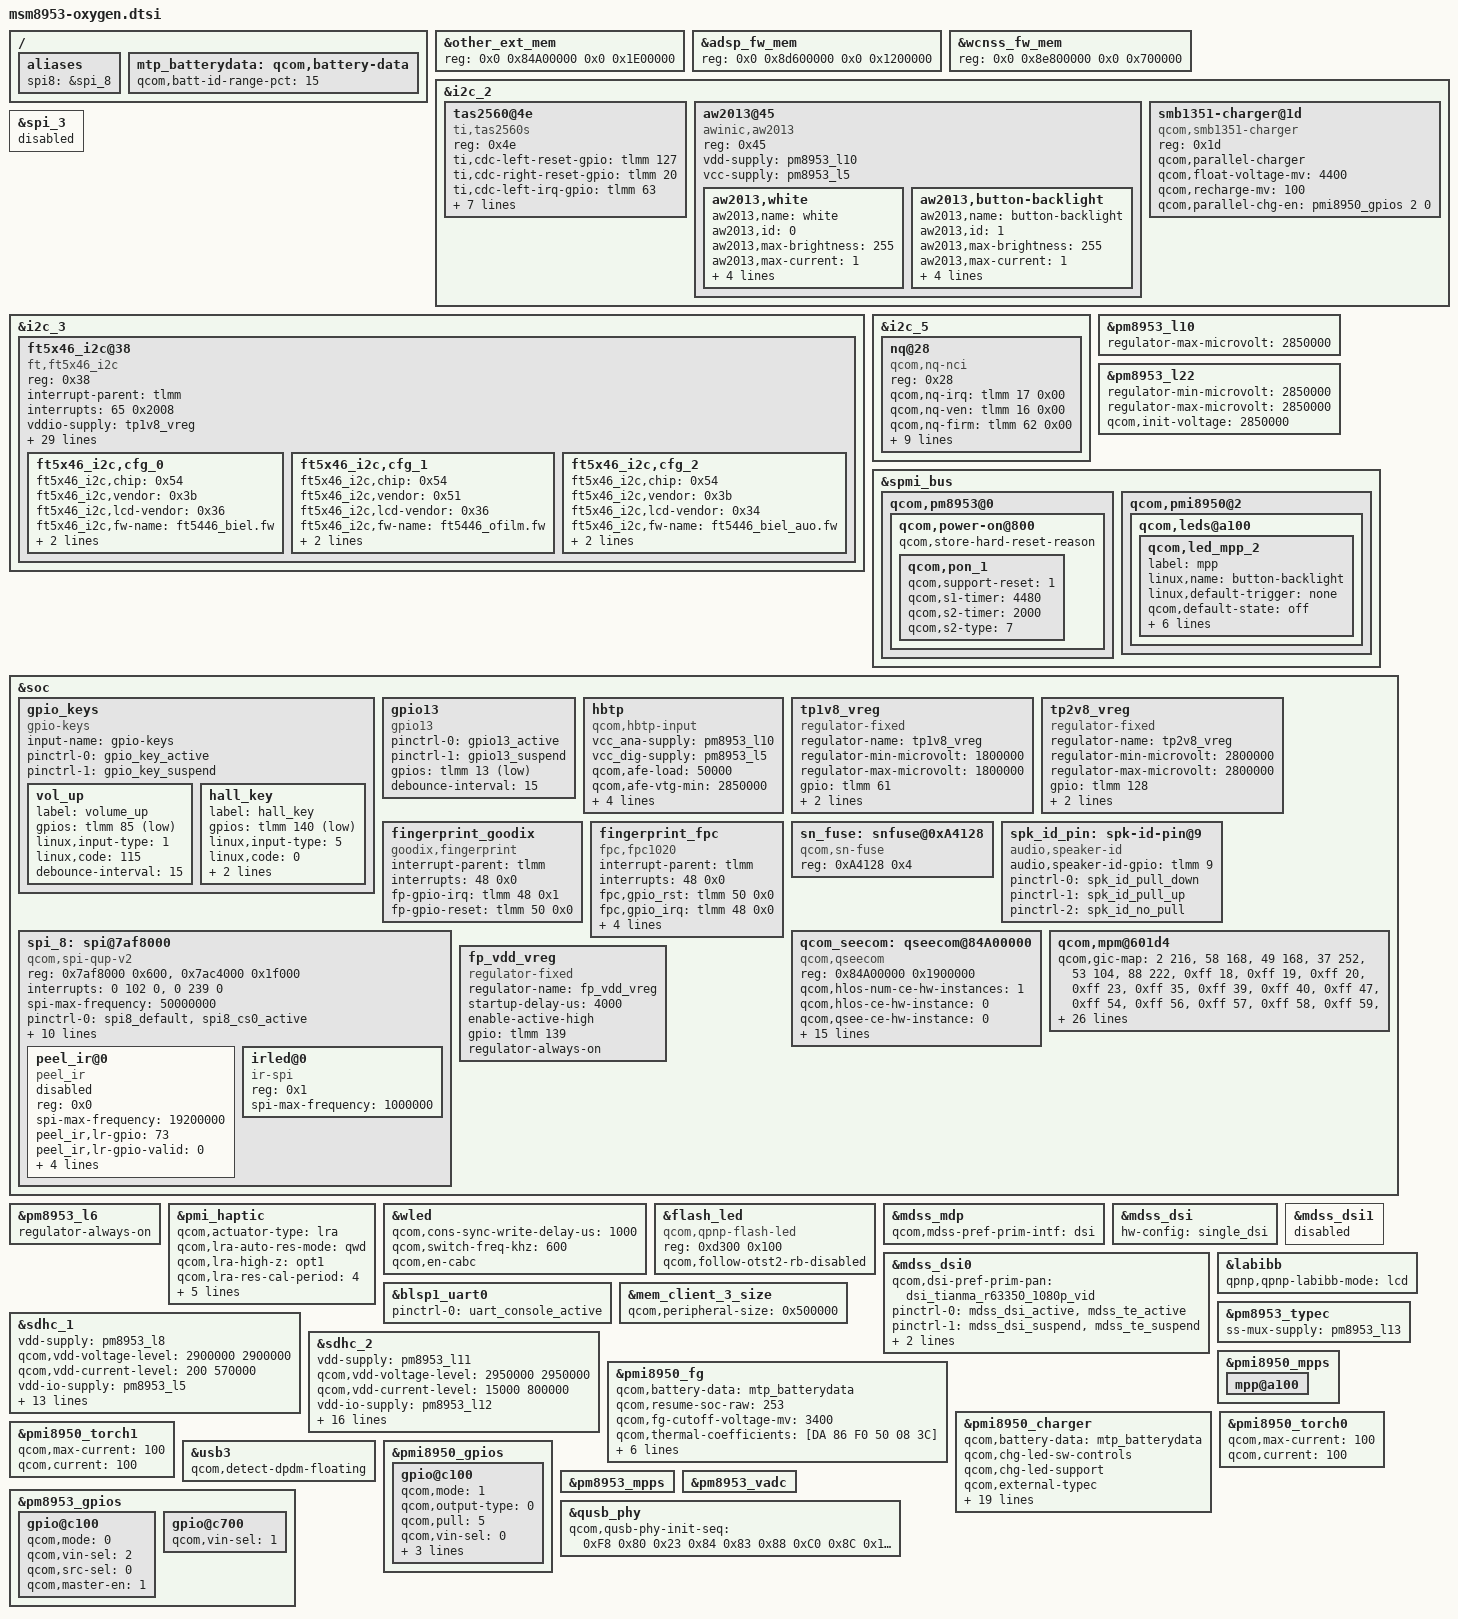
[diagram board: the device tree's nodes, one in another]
/*
 * Copyright (c) 2015-2016, The Linux Foundation. All rights reserved.
 * Copyright (C) 2017 XiaoMi, Inc.
 *
 * This program is free software; you can redistribute it and/or modify
 * it under the terms of the GNU General Public License version 2 and
 * only version 2 as published by the Free Software Foundation.
 *
 * This program is distributed in the hope that it will be useful,
 * but WITHOUT ANY WARRANTY; without even the implied warranty of
 * MERCHANTABILITY or FITNESS FOR A PARTICULAR PURPOSE.  See the
 * GNU General Public License for more details.
 */

#include "msm8953-oxygen-audio.dtsi"
#include "msm8953-oxygen-camera-sensor-mtp.dtsi"
//#include "msm8953-oxygen-mdss-panels.dtsi"
#include "msm8953-oxygen-pinctrl.dtsi"

#include "dsi-panel-tianma-r63350-1080p-video.dtsi"
#include "dsi-panel-auo-r61322-1080p-video.dtsi"

/ {
	aliases {
		spi8 = &spi_8;
	};
};

&other_ext_mem {
    reg = <0x0 0x84A00000 0x0 0x1E00000>;
};

&adsp_fw_mem {
    reg = <0x0 0x8d600000 0x0 0x1200000>;
};

&wcnss_fw_mem {
    reg = <0x0 0x8e800000 0x0 0x700000>;
};

&i2c_2 {
    /delete-node/ adv7533@39;
};

&spi_3 {
	status = "disabled";
};

&i2c_3 { /* BLSP1 QUP3 (TP) */
	status = "okay";
	ft5x46_i2c@38 {
		compatible = "ft,ft5x46_i2c";
		reg = <0x38>;
		interrupt-parent = <&tlmm>;
		interrupts = <65 0x2008>;
		vddio-supply = <&tp1v8_vreg>;
		vdd-supply = <&tp2v8_vreg>;
		/* pins used by touchscreen */
		pinctrl-names = "pmx_ts_active","pmx_ts_suspend";
		pinctrl-0 = <&ts_int_active &ts_reset_active>;
		pinctrl-1 = <&ts_int_suspend &ts_reset_suspend>;
		ft5x46_i2c,i2c-pull-up;
		ft5x46_i2c,irqflags = <0x2008>;
		ft5x46_i2c,x-max = <1080>;
		ft5x46_i2c,y-max = <1920>;
		ft5x46_i2c,z-max = <255>;
		ft5x46_i2c,w-max = <200>;
		ft5x46_i2c,reset-gpio = <&tlmm 64 0x00>;
		ft5x46_i2c,irq-gpio = <&tlmm 65 0x2008>;
		ft5x46_i2c,landing-jiffies = <1000>;
		ft5x46_i2c,landing-threshold = <16>;
		ft5x46_i2c,staying-threshold = <8>;
		ft5x46_i2c,raw-min = <7000>;
		ft5x46_i2c,raw-max = <10000>;
		ft5x46_i2c,has-key;
		ft5x46_i2c,key-rx1 = <4>;
		ft5x46_i2c,key-rx2 = <8>;
		ft5x46_i2c,key-rx3 = <12>;
		ft5x46_i2c,open-min = <4000>;
		ft5x46_i2c,imin-cc = <500>;
		ft5x46_i2c,imin-cg = <500>;
		ft5x46_i2c,fw-delay-55-ms = <2>;
		ft5x46_i2c,fw-delay-aa-ms = <2>;
		ft5x46_i2c,fw-upgrade-id1 = <0x54>;
		ft5x46_i2c,fw-upgrade-id2 = <0x2C>;
		ft5x46_i2c,fw-delay-readid-ms = <20>;
		ft5x46_i2c,firmware-array-size = <3>;
		ft5x46_i2c,cfg_0 {
			ft5x46_i2c,chip = <0x54>;
			ft5x46_i2c,vendor = <0x3b>;
			ft5x46_i2c,lcd-vendor = <0x36>;
			ft5x46_i2c,fw-name = "ft5446_biel.fw";
			ft5x46_i2c,tx-num = <24>;
			ft5x46_i2c,rx-num = <13>;
		};
		ft5x46_i2c,cfg_1 {
			ft5x46_i2c,chip = <0x54>;
			ft5x46_i2c,vendor = <0x51>;
			ft5x46_i2c,lcd-vendor = <0x36>;
			ft5x46_i2c,fw-name = "ft5446_ofilm.fw";
			ft5x46_i2c,tx-num = <24>;
			ft5x46_i2c,rx-num = <13>;
		};
		ft5x46_i2c,cfg_2 {
			ft5x46_i2c,chip = <0x54>;
			ft5x46_i2c,vendor = <0x3b>;
			ft5x46_i2c,lcd-vendor = <0x34>;
			ft5x46_i2c,fw-name = "ft5446_biel_auo.fw";
			ft5x46_i2c,tx-num = <24>;
			ft5x46_i2c,rx-num = <13>;
		};
	};
};

&i2c_2 { /* BLSP2 QUP1 (TAS2560) */
	tas2560@4e {
		compatible = "ti,tas2560s";
		reg = <0x4e>;
		ti,cdc-left-reset-gpio = <&tlmm 127 0>;
		ti,cdc-right-reset-gpio = <&tlmm 20 0>;
		ti,cdc-left-irq-gpio = <&tlmm 63 0>;
		ti,cdc-right-irq-gpio = <&tlmm 21 0>;
		ti,left-channel = <0x4f>;
		ti,right-channel = <0x4c>;
		ti,left-load = <0>;   /* 0, 8Ohm; 1, 6Ohm; 2, 4Ohm */
		ti,right-load-aac = <0>;   /* 0, 8Ohm; 1, 6Ohm; 2, 4Ohm */
		ti,right-load-ssi = <0>;   /* 0, 8Ohm; 1, 6Ohm; 2, 4Ohm */
		ti,spk-id-pin = <&spk_id_pin>;

	};

	aw2013@45 {
		compatible = "awinic,aw2013";
		reg = <0x45>;
		vdd-supply = <&pm8953_l10>;
		vcc-supply = <&pm8953_l5>;

		aw2013,white {
			aw2013,name = "white";
			aw2013,id = <0>;
			aw2013,max-brightness = <255>;
			aw2013,max-current = <1>;
			aw2013,rise-time-ms = <3>;
			aw2013,hold-time-ms = <2>;
			aw2013,fall-time-ms = <3>;
			aw2013,off-time-ms = <2>;
		};
		aw2013,button-backlight {
			aw2013,name = "button-backlight";
			aw2013,id = <1>;
			aw2013,max-brightness = <255>;
			aw2013,max-current = <1>;
			aw2013,rise-time-ms = <3>;
			aw2013,hold-time-ms = <2>;
			aw2013,fall-time-ms = <3>;
			aw2013,off-time-ms = <2>;
		};
	};
};

&i2c_5 { /* BLSP2 QUP1 (NFC) */
	nq@28 {
		compatible = "qcom,nq-nci";
		reg = <0x28>;
		qcom,nq-irq = <&tlmm 17 0x00>;
		qcom,nq-ven = <&tlmm 16 0x00>;
		qcom,nq-firm = <&tlmm 62 0x00>;
		qcom,nq-clkreq = <&pm8953_gpios 2 0x00>;
		qcom,nq-esepwr = <&tlmm 141 0x00>;
		interrupt-parent = <&tlmm>;
		qcom,clk-src = "BBCLK2";
		interrupts = <17 0>;
		interrupt-names = "nfc_irq";
		pinctrl-names = "nfc_active", "nfc_suspend";
		pinctrl-0 = <&nfc_int_active &nfc_disable_active>;
		pinctrl-1 = <&nfc_int_suspend &nfc_disable_suspend>;
		clocks = <&clock_gcc clk_bb_clk2_pin>;
		clock-names = "ref_clk";
	};

};

&pm8953_l10 {
	regulator-max-microvolt = <2850000>;
};

&pm8953_l22 {
    regulator-min-microvolt = <2850000>;
    regulator-max-microvolt = <2850000>;
    qcom,init-voltage = <2850000>;
};

&spmi_bus {
    qcom,pm8953@0 {
        qcom,power-on@800 {
            qcom,store-hard-reset-reason;
            qcom,pon_1 {
				qcom,support-reset = <1>;
				qcom,s1-timer = <4480>;
				qcom,s2-timer = <2000>;
				qcom,s2-type = <7>;
			};
		};
    };

	qcom,pmi8950@2 {
        qcom,leds@a100 {
			qcom,led_mpp_2 {
				label = "mpp";
				linux,name = "button-backlight";
				linux,default-trigger = "none";
				qcom,default-state = "off";
				qcom,max-current = <40>;
				qcom,current-setting = <5>;
				qcom,id = <6>;
				qcom,source-sel = <1>;
				qcom,mode-ctrl = <0x60>;
				qcom,mode = "manual";
			};
        };
	};
};

&soc {
	gpio_keys {
		compatible = "gpio-keys";
		input-name = "gpio-keys";
		pinctrl-names = "tlmm_gpio_key_active","tlmm_gpio_key_suspend";
		pinctrl-0 = <&gpio_key_active>;
		pinctrl-1 = <&gpio_key_suspend>;

		vol_up {
			label = "volume_up";
			gpios = <&tlmm 85 0x1>;
			linux,input-type = <1>;
			linux,code = <115>;
			debounce-interval = <15>;
		};
		hall_key {
			label = "hall_key";
			gpios = <&tlmm 140 0x01>;
			linux,input-type = <5>;
			linux,code = <0>;
			gpio-key,wakeup;
			debounce-interval = <15>;
		};

	};

	gpio13 {
		pinctrl-names = "tlmm_gpio13_active","tlmm_gpio13_suspend";
		pinctrl-0 = <&gpio13_active>;
		pinctrl-1 = <&gpio13_suspend>;
		compatible = "gpio13";
		gpios = <&tlmm 13 0x01>;
		debounce-interval = <15>;
	};

	hbtp {
		compatible = "qcom,hbtp-input";
		vcc_ana-supply = <&pm8953_l10>;
		vcc_dig-supply = <&pm8953_l5>;
		qcom,afe-load = <50000>;
		qcom,afe-vtg-min = <2850000>;
		qcom,afe-vtg-max = <2850000>;
		qcom,dig-load = <15000>;
		qcom,dig-vtg-min = <1800000>;
		qcom,dig-vtg-max = <1800000>;
	};

	tp1v8_vreg: tp1v8_vreg {
		compatible = "regulator-fixed";
		regulator-name = "tp1v8_vreg";
		regulator-min-microvolt = <1800000>;
		regulator-max-microvolt = <1800000>;
		gpio = <&tlmm 61 0>;
		startup-delay-us = <5000>;
		enable-active-high;
	};

	tp2v8_vreg: tp2v8_vreg {
		compatible = "regulator-fixed";
		regulator-name = "tp2v8_vreg";
		regulator-min-microvolt = <2800000>;
		regulator-max-microvolt = <2800000>;
		gpio = <&tlmm  128 0>;
		startup-delay-us = <5000>;
		enable-active-high;
	};

	fingerprint_goodix {
		compatible = "goodix,fingerprint";
		interrupt-parent = <&tlmm>;
		interrupts = <48 0x0>;
		fp-gpio-irq = <&tlmm 48 0x1>;
		fp-gpio-reset = <&tlmm 50 0x0>;
		status = "okay";
	};
	fingerprint_fpc {
		status = "okay";
		compatible = "fpc,fpc1020";
		interrupt-parent = <&tlmm>;
		interrupts = <48 0x0>;
		fpc,gpio_rst = <&tlmm 50 0x0>;
		fpc,gpio_irq = <&tlmm 48 0x0>;
		vdd_ana-supply  = <&fp_vdd_vreg>;
		/* fpc,enable-on-boot; */
		/* fpc,enable-wakeup; */

		pinctrl-names = "fpc1020_reset_reset",
				"fpc1020_reset_active",
				"fpc1020_irq_active";

		pinctrl-0 = <&msm_gpio_50>;
		pinctrl-1 = <&msm_gpio_50_output_high>;
		pinctrl-2 = <&msm_gpio_48>;
	};

	sn_fuse: snfuse@0xA4128 {
		compatible = "qcom,sn-fuse";
		reg = <0xA4128 0x4>;
		reg-names = "sn-base";
	};

	spk_id_pin: spk-id-pin@9 {
		compatible = "audio,speaker-id";
		audio,speaker-id-gpio = <&tlmm 9 0x00>;
		pinctrl-names = "pull_down", "pull_up", "no_pull";
		pinctrl-0 = <&spk_id_pull_down>;
		pinctrl-1 = <&spk_id_pull_up>;
		pinctrl-2 = <&spk_id_no_pull>;
	};

	spi_8: spi@7af8000 { /* BLSP2 QUP4 */
		status = "ok";
		compatible = "qcom,spi-qup-v2";
		#address-cells = <1>;
		#size-cells = <0>;
		reg-names = "spi_physical", "spi_bam_physical";
		reg = <0x7af8000 0x600>,
			<0x7ac4000 0x1f000>;
		interrupt-names = "spi_irq", "spi_bam_irq";
		interrupts = <0 102 0>, <0 239 0>;
		spi-max-frequency = <50000000>;
		pinctrl-names = "spi_default", "spi_sleep";
		pinctrl-0 = <&spi8_default &spi8_cs0_active>;
		pinctrl-1 = <&spi8_sleep &spi8_cs0_sleep>;
		clocks = <&clock_gcc clk_gcc_blsp2_ahb_clk>,
			<&clock_gcc clk_gcc_blsp2_qup4_spi_apps_clk>;
		clock-names = "iface_clk", "core_clk";
		qcom,infinite-mode = <0>;
		qcom,use-bam;
		qcom,use-pinctrl;
		qcom,ver-reg-exists;
		qcom,bam-consumer-pipe-index = <10>;
		qcom,bam-producer-pipe-index = <11>;
		qcom,master-id = <84>;

		peel_ir@0 {
			compatible = "peel_ir";
			reg = <0x0>;
			spi-max-frequency = <19200000>;
			peel_ir,lr-gpio = <73>;
			peel_ir,lr-gpio-valid = <0>;
			peel_ir,spi-bpw = <32>;
			peel_ir,spi-clk-speed = <960000>;
			peel_ir,spi-mode = <0>;
			peel_ir,peel-field = <2345>;
			status = "disabled";
		};
		irled@0 {
			compatible = "ir-spi";
			reg = <0x1>;
			status = "ok";
			spi-max-frequency = <1000000>;
		};
	};

	/delete-node/ qseecom@85b00000;

	qcom_seecom: qseecom@84A00000 {
		compatible = "qcom,qseecom";
		reg = <0x84A00000 0x1900000>;
		reg-names = "secapp-region";
		qcom,hlos-num-ce-hw-instances = <1>;
		qcom,hlos-ce-hw-instance = <0>;
		qcom,qsee-ce-hw-instance = <0>;
		qcom,disk-encrypt-pipe-pair = <2>;
		qcom,support-fde;
		qcom,msm-bus,name = "qseecom-noc";
		qcom,msm-bus,num-cases = <4>;
		qcom,msm-bus,num-paths = <1>;
		qcom,support-bus-scaling;
		qcom,appsbl-qseecom-support;
		qcom,msm-bus,vectors-KBps =
			<55 512 0 0>,
			<55 512 0 0>,
			<55 512 120000 1200000>,
			<55 512 393600 3936000>;
		clocks = <&clock_gcc clk_crypto_clk_src>,
			 <&clock_gcc clk_gcc_crypto_clk>,
			 <&clock_gcc clk_gcc_crypto_ahb_clk>,
			 <&clock_gcc clk_gcc_crypto_axi_clk>;
		clock-names = "core_clk_src", "core_clk",
				"iface_clk", "bus_clk";
		qcom,ce-opp-freq = <100000000>;
	};

    qcom,mpm@601d4 {
        qcom,gic-map = <2 216>, /* tsens_upper_lower_int */
			<58 168>,   /* qusb2phy_dmse_hv -> hs_phy_irq*/
			<49 168>,   /* qusb2phy_dpse_hv -> hs_phy_irq*/
			<37 252>,   /* qmp_usb3_lfps_rxterm_irq -> ss_phy_irq */
			<53 104>, /* mdss_irq */
			<88 222>, /* ee0_krait_hlos_spmi_periph_irq */
			<0xff 18>,  /* APC_qgicQTmrSecPhysIrptReq */
			<0xff 19>,  /* APC_qgicQTmrNonSecPhysIrptReq */
			<0xff 20>,  /* qgicQTmrVirtIrptReq */
			<0xff 23>,  /* apss_hm */
			<0xff 35>,  /* WDT_barkInt */
			<0xff 39>,  /* arch_mem_timer */
			<0xff 40>,  /* qtmr_phy_irq[0] */
			<0xff 47>,  /* rbif_irq[0] */
			<0xff 54>,  /* gladiator-error */
			<0xff 56>,  /* q6_wdog_expired_irq */
			<0xff 57>,  /* mss_to_apps_irq(0) */
			<0xff 58>,  /* mss_to_apps_irq(1) */
			<0xff 59>,  /* mss_to_apps_irq(2) */
			<0xff 60>,  /* mss_to_apps_irq(3) */
			<0xff 61>,  /* mss_a2_bam_irq */
			<0xff 65>,  /* o_gc_sys_irq[0] */
			<0xff 69>,  /* vbif_irpt */
			<0xff 73>,  /* app_tcu_gbl_flt_irpt_ns */
			<0xff 74>,  /* smmu_bus_intr[2] */
			<0xff 75>,  /* smmu_bus_intr[3] */
			<0xff 78>,  /* smmu_bus_intr[5] */
			<0xff 79>,  /* smmu_bus_intr[6] */
			<0xff 85>,  /* smmu_bus_intr[31] */
			<0xff 86>,  /* smmu_bus_intr[32] */
			<0xff 90>,  /* smmu_bus_intr[33] */
			<0xff 92>,  /* smmu_bus_intr[34] */
			<0xff 93>,  /* smmu_bus_intr[35] */
			<0xff 97>,  /* smmu_bus_intr[10] */
			<0xff 102>, /* smmu_bus_intr[14] */
			<0xff 108>, /* smmu_bus_intr[36] */
			<0xff 109>, /* smmu_bus_intr[37] */
			<0xff 112>, /* smmu_bus_intr[38] */
			<0xff 114>, /* qdsd_intr_out */
			<0xff 126>, /* app_tcu_cxt_irpt_vec[11] */
			<0xff 128>, /* blsp1_peripheral_irq[3] */
			<0xff 131>, /* qup_irq */
			<0xff 136>, /* app_tcu_cxt_irpt_vec[15] */
			<0xff 137>, /* app_tcu_cxt_irpt_vec[16] */
			<0xff 138>, /* app_tcu_cxt_irpt_vec[17] */
			<0xff 139>, /* uart_dm_intr */
			<0xff 140>, /* uart_dm_intr */
			<0xff 141>, /* app_tcu_cxt_irpt_vec[18] */
			<0xff 142>, /* smmu_bus_intr[47] */
			<0xff 143>, /* smmu_bus_intr[48] */
			<0xff 144>, /* smmu_bus_intr[49] */
			<0xff 145>, /* smmu_bus_intr[50] */
			<0xff 146>, /* smmu_bus_intr[51] */
			<0xff 147>, /* smmu_bus_intr[52] */
			<0xff 148>, /* smmu_bus_intr[53] */
			<0xff 149>, /* smmu_bus_intr[54] */
			<0xff 150>, /* smmu_bus_intr[55] */
			<0xff 151>, /* smmu_bus_intr[56] */
			<0xff 152>, /* smmu_bus_intr[57] */
			<0xff 153>, /* smmu_bus_intr[58] */
			<0xff 155>, /* sdc1_irq(0) */
			<0xff 157>, /* sdc2_irq(0) */
			<0xff 166>, /* usb30_pwr_evnt_irq */
			<0xff 167>, /* usb30_bam_irq[0] */
			<0xff 170>, /* sdc1_pwr_cmd_irq */
			<0xff 172>, /* usb30_ctrl_irq[0] */
			<0xff 173>, /* o_wcss_apss_smd_hi */
			<0xff 174>, /* o_wcss_apss_smd_med */
			<0xff 175>, /* o_wcss_apss_smd_low */
			<0xff 176>, /* o_wcss_apss_smsm_irq */
			<0xff 177>, /* o_wcss_apss_wlan_data_xfer_done */
			<0xff 178>, /* o_wcss_apss_wlan_rx_data_avail */
			<0xff 179>, /* o_wcss_apss_asic_intr */
			<0xff 181>, /* o_wcss_apss_wdog_bite_and_reset_rdy */
			<0xff 188>, /* lpass_irq_out_apcs(0) */
			<0xff 189>, /* lpass_irq_out_apcs(1) */
			<0xff 190>, /* lpass_irq_out_apcs(2) */
			<0xff 191>, /* lpass_irq_out_apcs(3) */
			<0xff 192>, /* lpass_irq_out_apcs(4) */
			<0xff 193>, /* lpass_irq_out_apcs(5) */
			<0xff 194>, /* lpass_irq_out_apcs(6) */
			<0xff 195>, /* lpass_irq_out_apcs(7) */
			<0xff 196>, /* lpass_irq_out_apcs(8) */
			<0xff 197>, /* lpass_irq_out_apcs(9) */
			<0xff 198>, /* coresight-tmc-etr interrupt */
			<0xff 200>, /* rpm_ipc(4) */
			<0xff 201>, /* rpm_ipc(5) */
			<0xff 202>, /* rpm_ipc(6) */
			<0xff 203>, /* rpm_ipc(7) */
			<0xff 204>, /* rpm_ipc(24) */
			<0xff 205>, /* rpm_ipc(25) */
			<0xff 206>, /* rpm_ipc(26) */
			<0xff 207>, /* rpm_ipc(27) */
			<0xff 212>, /* lpass_slimbus_bam_ee1_irq */
			<0xff 215>, /* o_bimc_intr[0] */
			<0xff 224>, /* spdm_realtime_irq[1] */
			<0xff 231>, /* arm-smmu global fault */
			<0xff 239>, /* crypto_bam_irq[1]*/
			<0xff 240>, /* summary_irq_kpss */
			<0xff 253>, /* sdc2_pwr_cmd_irq */
			<0xff 257>, /* osmmu_Cirpt[0] */
			<0xff 260>, /* ipa_irq[0] */
			<0xff 262>, /* ipa_bam_irq[0] */
			<0xff 263>, /* ipa_bam_irq[2] */
			<0xff 264>, /* arm-smmu context fault */
			<0xff 269>, /* rpm_wdog_expired_irq */
			<0xff 270>, /* blsp1_bam_irq[0] */
			<0xff 271>, /* Added by Xiaomi */
			<0xff 273>, /* smmu_bus_intr[18] */
			<0xff 274>, /* smmu_bus_intr[19] */
			<0xff 275>, /* rpm_ipc(30) */
			<0xff 276>, /* rpm_ipc(31) */
			<0xff 285>, /* app_tcu_cxt_irpt_vec[0] */
			<0xff 286>, /* app_tcu_cxt_irpt_vec[1] */
			<0xff 287>, /* app_tcu_cxt_irpt_vec[2] */
			<0xff 305>, /* L2_EXTERRIRQ_C0 */
			<0xff 306>, /* L2_EXTERRIRQ_C1 */
			<0xff 307>, /* L2_INTERRIRQ_C0 */
			<0xff 308>, /* L2_INTERRIRQ_C1 */
			<0xff 314>, /* CCISAW_svicInt */
			<0xff 321>, /* q6ss_irq_out(4) */
			<0xff 322>, /* q6ss_irq_out(5) */
			<0xff 323>, /* q6ss_irq_out(6) */
			<0xff 325>, /* q6ss_wdog_exp_irq */
			<0xff 344>, /* sdcc_ice_nonsec_level_irq */
			<0xff 346>; /* tsens_critical_int */
    };

    /delete-node/ eldo2;

    fp_vdd_vreg: fp_vdd_vreg {
		compatible = "regulator-fixed";
		regulator-name = "fp_vdd_vreg";
		startup-delay-us = <4000>;
		enable-active-high;
		gpio = <&tlmm 139 0>;
	};
};


&fp_vdd_vreg {
	regulator-always-on;
};

&pm8953_l6 {
	regulator-always-on;
};

&pmi_haptic{
	qcom,actuator-type = "lra";
	qcom,lra-auto-res-mode="qwd";
	qcom,lra-high-z="opt1";
	qcom,lra-res-cal-period = <4>;
	qcom,wave-play-rate-us = <5100>;
	qcom,wave-shape = "sine";
	qcom,vmax-mv = <2088>;
	qcom,brake-pattern = [03 02 01 00];
	qcom,misc-trim-error-rc19p2-clk-reg-present;
};

&wled {
	qcom,cons-sync-write-delay-us = <1000>;
    qcom,switch-freq-khz = <600>;
    /delete-property/ qcom,en-ext-pfet-sc-pro;
    qcom,en-cabc;
};

&flash_led {
	compatible = "qcom,qpnp-flash-led";
	reg = <0xd300 0x100>;
	qcom,follow-otst2-rb-disabled;
};

&mdss_mdp {
	qcom,mdss-pref-prim-intf = "dsi";
};

&mdss_dsi {
	hw-config = "single_dsi";
};

&mdss_dsi0 {
	qcom,dsi-pref-prim-pan = <&dsi_tianma_r63350_1080p_vid>;
	pinctrl-names = "mdss_default", "mdss_sleep";
	pinctrl-0 = <&mdss_dsi_active &mdss_te_active>;
	pinctrl-1 = <&mdss_dsi_suspend &mdss_te_suspend>;

	qcom,platform-te-gpio = <&tlmm 24 0>;
	qcom,platform-reset-gpio = <&tlmm 35 0>;

	/delete-property/ vdd-supply;
};

&mdss_dsi1 {
	status = "disabled";
};

&labibb {
	status = "ok";
	qpnp,qpnp-labibb-mode = "lcd";
};

&blsp1_uart0 {
	status = "ok";
	pinctrl-names = "default";
	pinctrl-0 = <&uart_console_active>;
};

&mem_client_3_size {
	qcom,peripheral-size = <0x500000>;
};

&sdhc_1 {
	/* device core power supply */
	vdd-supply = <&pm8953_l8>;
	qcom,vdd-voltage-level = <2900000 2900000>;
	qcom,vdd-current-level = <200 570000>;

	/* device communication power supply */
	vdd-io-supply = <&pm8953_l5>;
	qcom,vdd-io-always-on;
	qcom,vdd-io-lpm-sup;
	qcom,vdd-io-voltage-level = <1800000 1800000>;
	qcom,vdd-io-current-level = <200 325000>;

	pinctrl-names = "active", "sleep";
	pinctrl-0 = <&sdc1_clk_on &sdc1_cmd_on &sdc1_data_on  &sdc1_rclk_on>;
	pinctrl-1 = <&sdc1_clk_off &sdc1_cmd_off &sdc1_data_off &sdc1_rclk_off>;

	qcom,clk-rates = <400000 20000000 25000000 50000000 100000000 192000000
								384000000>;
	qcom,nonremovable;
	qcom,bus-speed-mode = "HS400_1p8v", "HS200_1p8v", "DDR_1p8v";

	status = "ok";
};

&sdhc_2 {
	/* device core power supply */
	vdd-supply = <&pm8953_l11>;
	qcom,vdd-voltage-level = <2950000 2950000>;
	qcom,vdd-current-level = <15000 800000>;

	/* device communication power supply */
	vdd-io-supply = <&pm8953_l12>;
	qcom,vdd-io-voltage-level = <1800000 2950000>;
	qcom,vdd-io-current-level = <200 22000>;

	pinctrl-names = "active", "sleep";
	pinctrl-0 = <&sdc2_clk_on &sdc2_cmd_on &sdc2_data_on &sdc2_cd_on>;
	pinctrl-1 = <&sdc2_clk_off &sdc2_cmd_off &sdc2_data_off>;

	#address-cells = <0>;
	interrupt-parent = <&sdhc_2>;
	interrupts = <0 1 2>;
	#interrupt-cells = <1>;
	interrupt-map-mask = <0xffffffff>;
	interrupt-map = <0 &intc 0 125 0
		1 &intc 0 221 0
		2 &tlmm 133 0>;
	interrupt-names = "hc_irq", "pwr_irq", "status_irq";
	cd-gpios = <&tlmm 133 0x1>;

	qcom,clk-rates = <400000 20000000 25000000 50000000 100000000
								200000000>;
	qcom,bus-speed-mode = "SDR12", "SDR25", "SDR50", "DDR50", "SDR104";

	status = "ok";
};

&pm8953_typec {
	ss-mux-supply = <&pm8953_l13>;
	/delete-property/ qcom,ssmux-gpio;
	/delete-property/ pinctrl-names;
	/delete-property/ pinctrl-0;

};

/{
	mtp_batterydata: qcom,battery-data {
		qcom,batt-id-range-pct = <15>;
		#include "batterydata-d4-sunwoda-5300mAh.dtsi"
		#include "batterydata-d4-coslight-5300mAh.dtsi"
	};
};

&pmi8950_fg {
	qcom,battery-data = <&mtp_batterydata>;
	qcom,resume-soc-raw = <253>;
	qcom,fg-cutoff-voltage-mv = <3400>;
	qcom,thermal-coefficients = [DA 86 F0 50 08 3C];
	qcom,vbat-estimate-diff-mv = <200>;
	qcom,warm-bat-decidegc = <450>;
	qcom,cool-bat-decidegc = <150>;
	qcom,hot-bat-decidegc  = <600>;
	qcom,cold-bat-decidegc = <0>;
	qcom,ext-sense-type;
};

&pmi8950_mpps {
    mpp@a100 {
        status = "okay";
    };
};

&pmi8950_charger {
	qcom,battery-data = <&mtp_batterydata>;
	qcom,chg-led-sw-controls;
	qcom,chg-led-support;
	qcom,external-typec;
	qcom,typec-psy-name = "typec";
	qcom,fastchg-current-ma = <3400>;
	qcom,float-voltage-mv = <4400>;
	qcom,thermal-mitigation = <2500 2000 1500 1000>;
	qcom,thermal-mitigation-screen-off = <3000 2800 2500 2000 1600 1200 1000 500>;
	qcom,thermal-mitigation-screen-on = <2000 1400 1100 900 700 650 600 500>;
	qcom,thermal-mitigation-hvdcp-screen-off = <1800 1600 1400 1200 1000 900 700 500>;
	qcom,thermal-mitigation-hvdcp-screen-on = <1200 900 700 600 550 500 500 500>;
	qcom,thermal-fcc-screen-off = <3400 3200 2800 2400 1600 1200 1000 500>;
	qcom,thermal-fcc-screen-on = <1800 1100 1000 900 700 500 300 500>;
	qcom,fastchg-current-comp = <1200>;
	qcom,float-voltage-comp = <16>;
	qcom,override-usb-current;
	/delete-property/ qcom,autoadjust-vfloat;
};

&pmi8950_torch0 {
    qcom,max-current = <100>;
    qcom,current = <100>;
};

&pmi8950_torch1 {
    qcom,max-current = <100>;
    qcom,current = <100>;
};

&usb3 {
	qcom,detect-dpdm-floating;
};

&pmi8950_gpios {
	/* GPIO 2 (CHG_STAT) */
	gpio@c100 {
		qcom,mode = <1>;	/* Digital output */
		qcom,output-type = <0>;	/* CMOS */
		qcom,pull = <5>;	/* No pull */
		qcom,vin-sel = <0>;	/* VIN0 */
		qcom,src-sel = <0>;	/* Constant */
		qcom,invert = <0>;	/* Output low initially */
		qcom,master-en = <1>;	/* GPIO enabled */
		status = "okay";
	};
};

&pm8953_mpps {
	/delete-node/ mpp@a100;
};

&pm8953_vadc {
	/delete-node/ chan@11;
};

&i2c_2 {
	smb1351-charger@1d {
		compatible = "qcom,smb1351-charger";
		reg = <0x1d>;
		qcom,parallel-charger;
		qcom,float-voltage-mv = <4400>;
		qcom,recharge-mv = <100>;
		qcom,parallel-chg-en = <&pmi8950_gpios 2 0>;
	};

};

&pm8953_gpios {
	/* GPIO 2 (NFC_CLK_REQ) */
	gpio@c100 {
		qcom,mode = <0>;
		qcom,vin-sel = <2>;
		qcom,src-sel = <0>;
		qcom,master-en = <1>;
		status = "okay";
	};

	/* GPIO 8 (USB_HS_ID) */
	gpio@c700 {
		/* pm8953 gpio_8 default voltage source is vin3, should change to vin1 */
		qcom,vin-sel = <1>;
		status = "okay";
	};
};

&qusb_phy {
		qcom,qusb-phy-init-seq = <0xF8 0x80
					0x23 0x84
					0x83 0x88
					0xC0 0x8C
					0x14 0x9C
					0x30 0x08
					0x79 0x0C
					0x21 0x10
					0x00 0x90
					0x9F 0x1C
					0x00 0x18>;
};
